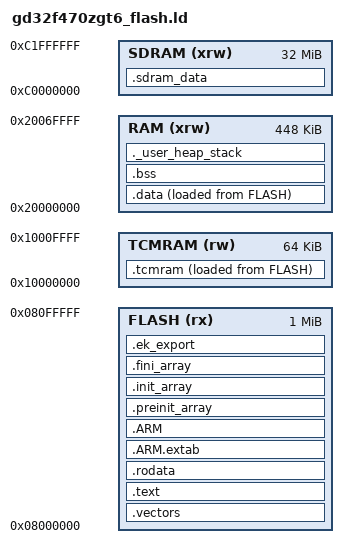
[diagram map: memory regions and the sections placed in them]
/* Memory Map */

/* Entry Point */
ENTRY(Reset_Handler)

/* Highest address of the user mode stack */
_sp = ORIGIN(RAM) + LENGTH(RAM); /* end of "RAM" Ram type memory */

_Min_Heap_Size = 0x200; /* required amount of heap */
_Min_Stack_Size = 0x400; /* required amount of stack */

/* Memories definition */
MEMORY
{
    FLASH (rx)  : ORIGIN = 0x08000000, LENGTH = 1024K
    RAM (xrw)   : ORIGIN = 0x20000000, LENGTH = 448K
    TCMRAM (rw) : ORIGIN = 0x10000000, LENGTH = 64K
    SDRAM (xrw)     : ORIGIN = 0xC0000000, LENGTH = 32M
}

/* Sections */
SECTIONS
{
    /* The startup code into "FLASH" Rom type memory */
    .vectors :
    {
        . = ALIGN(4);
        KEEP(*(.vectors)) /* Startup code */
        . = ALIGN(4);
    } >FLASH

    /* The program code and other data into "FLASH" Rom type memory */
    .text :
    {
        . = ALIGN(4);
        *(.text)           /* .text sections (code) */
        *(.text*)          /* .text* sections (code) */
        *(.glue_7)         /* glue arm to thumb code */
        *(.glue_7t)        /* glue thumb to arm code */
        *(.eh_frame)

        KEEP (*(.init))
        KEEP (*(.fini))

        . = ALIGN(4);
        _etext = .;        /* define a global symbols at end of code */
    } >FLASH

    /* Constant data into "FLASH" Rom type memory */
    .rodata :
    {
        . = ALIGN(4);
        *(.rodata)         /* .rodata sections (constants, strings, etc.) */
        *(.rodata*)        /* .rodata* sections (constants, strings, etc.) */
        . = ALIGN(4);
    } >FLASH

    .ARM.extab (READONLY) : /* The READONLY keyword is only supported in GCC11 and later, remove it if using GCC10 or earlier. */
    {
        . = ALIGN(4);
        *(.ARM.extab* .gnu.linkonce.armextab.*)
        . = ALIGN(4);
    } >FLASH

    .ARM (READONLY) : /* The READONLY keyword is only supported in GCC11 and later, remove it if using GCC10 or earlier. */
    {
        . = ALIGN(4);
        __exidx_start = .;
        *(.ARM.exidx*)
        __exidx_end = .;
        . = ALIGN(4);
    } >FLASH

    .preinit_array (READONLY) : /* The READONLY keyword is only supported in GCC11 and later, remove it if using GCC10 or earlier. */
    {
        . = ALIGN(4);
        PROVIDE_HIDDEN (__preinit_array_start = .);
        KEEP (*(.preinit_array*))
        PROVIDE_HIDDEN (__preinit_array_end = .);
        . = ALIGN(4);
    } >FLASH

    .init_array (READONLY) : /* The READONLY keyword is only supported in GCC11 and later, remove it if using GCC10 or earlier. */
    {
        . = ALIGN(4);
        PROVIDE_HIDDEN (__init_array_start = .);
        KEEP (*(SORT(.init_array.*)))
        KEEP (*(.init_array*))
        PROVIDE_HIDDEN (__init_array_end = .);
        . = ALIGN(4);
    } >FLASH

    .fini_array (READONLY) : /* The READONLY keyword is only supported in GCC11 and later, remove it if using GCC10 or earlier. */
    {
        . = ALIGN(4);
        PROVIDE_HIDDEN (__fini_array_start = .);
        KEEP (*(SORT(.fini_array.*)))
        KEEP (*(.fini_array*))
        PROVIDE_HIDDEN (__fini_array_end = .);
        . = ALIGN(4);
    } >FLASH

    /* Used by the startup to initialize data */
    _sidata = LOADADDR(.data);

    /* Initialized data sections into "RAM" Ram type memory */
    .data :
    {
        . = ALIGN(4);
        _sdata = .;        /* create a global symbol at data start */
        *(.data)           /* .data sections */
        *(.data*)          /* .data* sections */
        *(.RamFunc)        /* .RamFunc sections */
        *(.RamFunc*)       /* .RamFunc* sections */

        . = ALIGN(4);
        _edata = .;        /* define a global symbol at data end */

    } >RAM AT> FLASH

    /* Uninitialized data section into "RAM" Ram type memory */
    . = ALIGN(4);
    .bss :
    {
        /* This is used by the startup in order to initialize the .bss section */
        _sbss = .;         /* define a global symbol at bss start */
        __bss_start__ = _sbss;
        *(.bss)
        *(.bss*)
        *(COMMON)

        . = ALIGN(4);
        _ebss = .;         /* define a global symbol at bss end */
        __bss_end__ = _ebss;
    } >RAM

    /* User_heap_stack section, used to check that there is enough "RAM" Ram  type memory left */
    ._user_heap_stack :
    {
        . = ALIGN(8);
        PROVIDE ( end = . );
        PROVIDE ( _end = . );
        . = . + _Min_Heap_Size;
        . = . + _Min_Stack_Size;
        . = ALIGN(8);
    } >RAM

    /* Used by the startup to initialize tcmram */
    _sitcmram = LOADADDR(.tcmram);
    
    /* Initialized tcmram sections into "TCMRAM" Ram type memory */
    .tcmram :
    {
        . = ALIGN(4);
        _stcmram = .;       /* create a global symbol at tcmram start */
        *(.tcmram)          /* .tcmram sections */
        *(.tcmram*)         /* .tcmram* sections */

        *(.ccmram)          /* .ccmram 与 ST 适配 */
        *(.ccmram*)

        . = ALIGN(4);
        _etcmram = .;       /* define a global symbol at tcmram end */
    } >TCMRAM AT> FLASH

    /* Remove information from the compiler libraries */
    /DISCARD/ :
    {
        libc.a ( * )
        libm.a ( * )
        libgcc.a ( * )
    }

    .ARM.attributes 0 : { *(.ARM.attributes) }

    /* EK EXPORT */
    .ek_export :
    {
    . = ALIGN(4);
    _ek_export_fn_start = .;
    KEEP(*(SORT(.ek_export_fn*)))
    . = ALIGN(4);
    _ek_export_fn_end = .;
    } > FLASH

    /* SDRAM Data */
    .sdram_data (NOLOAD) :
    {
    . = ALIGN(4);
    _sdram_data_start = .;
    *(.sdram_data)
    *(.sdram_data*)

    . = ALIGN(4);
    _sdram_data_end = .;

    } > SDRAM
}
